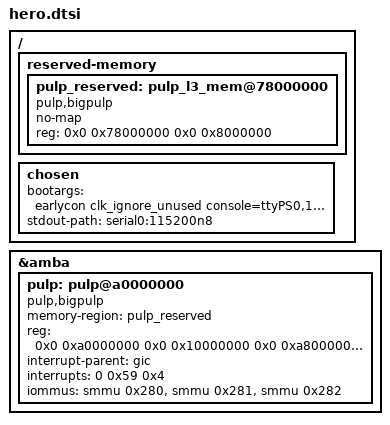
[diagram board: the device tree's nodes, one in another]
/* #include "xilinx/zynqmp-zcu102.dts" */

/ {
    reserved-memory {
        #address-cells = <2>;
        #size-cells = <2>;
        ranges;

        /* contiguous L3 memory for PULP: last 128MiB of DRAM */
        pulp_reserved: pulp_l3_mem@78000000 {
            compatible = "pulp,bigpulp";
            no-map;
            reg = <0x0 0x78000000 0x0 0x8000000>;
        };
    };

    /* Ensure serial terminal is enabled at boot. */
    chosen {
        bootargs = "earlycon clk_ignore_unused console=ttyPS0,115200";
        stdout-path = "serial0:115200n8";
    };
};

&amba {
    pulp: pulp@a0000000 {
        memory-region = <&pulp_reserved>;
        compatible = "pulp,bigpulp";
        reg = <0x0 0xa0000000 0x0 0x10000000
               0x0 0xa8000000 0x0 0x10000>;
        interrupt-parent = <&gic>;
        interrupts = <0 0x59 0x4>;
        iommus = <&smmu 0x280>, <&smmu 0x281>, <&smmu 0x282>; /* FIXME: check this */
    };
};

/* FIXME: test why this hangs */
/*&smmu {
    status = "okay";
};*/
